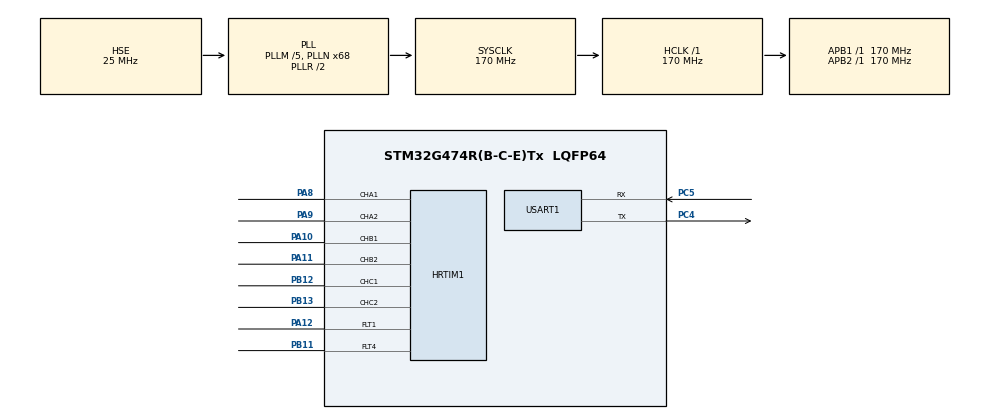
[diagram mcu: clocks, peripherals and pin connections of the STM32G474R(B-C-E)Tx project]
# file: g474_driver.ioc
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HRTIM1.CompareUnit1-Output_TA1TA2=HRTIM_COMPAREUNIT_1
HRTIM1.Periode_TA=34000
HRTIM1.PrescalerRatio_TA=HRTIM_PRESCALERRATIO_MUL4
Mcu.Family=STM32G4
Mcu.Name=STM32G474R(B-C-E)Tx
Mcu.Package=LQFP64
NVIC.PriorityGroup=NVIC_PRIORITYGROUP_4
PA10.Mode=Output_TB1TB2
PA10.Signal=HRTIM1_CHB1
PA11.Mode=Output_TB1TB2
PA11.Signal=HRTIM1_CHB2
PA12.Mode=Fault_Enable1
PA12.Signal=HRTIM1_FLT1
PA13.Mode=Serial_Wire
PA13.Signal=SYS_JTMS-SWDIO
PA14.Mode=Serial_Wire
PA14.Signal=SYS_JTCK-SWCLK
PA8.Mode=Output_TA1TA2
PA8.Signal=HRTIM1_CHA1
PA9.Mode=Output_TA1TA2
PA9.Signal=HRTIM1_CHA2
PB11.Mode=Fault_Enable4
PB11.Signal=HRTIM1_FLT4
PB12.Mode=Output_TC1TC2
PB12.Signal=HRTIM1_CHC1
PB13.Mode=Output_TC1TC2
PB13.Signal=HRTIM1_CHC2
PC4.Mode=Asynchronous
PC4.Signal=USART1_TX
PC5.Mode=Asynchronous
PC5.Signal=USART1_RX
PF0-OSC_IN.Mode=HSE-External-Oscillator
PF0-OSC_IN.Signal=RCC_OSC_IN
PF1-OSC_OUT.Mode=HSE-External-Oscillator
PF1-OSC_OUT.Signal=RCC_OSC_OUT
ProjectManager.HeapSize=0x200
ProjectManager.StackSize=0x400
ProjectManager.TargetToolchain=MDK-ARM V5.32
RCC.ADC12Freq_Value=170000000
RCC.ADC345Freq_Value=170000000
RCC.AHBFreq_Value=170000000
RCC.APB1Freq_Value=170000000
RCC.APB1TimFreq_Value=170000000
RCC.APB2Freq_Value=170000000
RCC.APB2TimFreq_Value=170000000
RCC.CortexFreq_Value=170000000
RCC.EXTERNAL_CLOCK_VALUE=12288000
RCC.HCLKFreq_Value=170000000
RCC.HSE_VALUE=25000000
RCC.HSI48_VALUE=48000000
RCC.HSI_VALUE=16000000
RCC.LSE_VALUE=32768
RCC.PLLM=RCC_PLLM_DIV5
RCC.PLLN=68
RCC.PLLSourceVirtual=RCC_PLLSOURCE_HSE
RCC.SYSCLKFreq_VALUE=170000000
RCC.SYSCLKSource=RCC_SYSCLKSOURCE_PLLCLK
RCC.USART1CLockSelection=RCC_USART1CLKSOURCE_HSI
RCC.USBFreq_Value=170000000
RCC.VCOOutputFreq_Value=340000000
USART1.VirtualMode-Asynchronous=VM_ASYNC
VP_HRTIM1_VS_hrtimMasterTimerNoOutput.Mode=MasterTimer
VP_SYS_VS_DBSignals.Mode=DisableDeadBatterySignals
board=custom

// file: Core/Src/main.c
/* USER CODE BEGIN Header */
/**
  ******************************************************************************
  * @file           : main.c
  * @brief          : Main program body
  ******************************************************************************
  * @attention
  *
  * Copyright (c) 2026 STMicroelectronics.
  * All rights reserved.
  *
  * This software is licensed under terms that can be found in the LICENSE file
  * in the root directory of this software component.
  * If no LICENSE file comes with this software, it is provided AS-IS.
  *
  ******************************************************************************
  */
/* USER CODE END Header */
#include "main.h"

/* USER CODE BEGIN Includes */
//#include "motor.h"
#include "uart.h"
/* USER CODE END Includes */

HRTIM_HandleTypeDef hhrtim1;

UART_HandleTypeDef huart1;

void SystemClock_Config(void);
static void MX_GPIO_Init(void);
static void MX_HRTIM1_Init(void);
static void MX_USART1_UART_Init(void);

int main(void)
{

  /* MCU Configuration--------------------------------------------------------*/

  /* Reset of all peripherals, Initializes the Flash interface and the Systick. */
  HAL_Init();

  /* Configure the system clock */
  SystemClock_Config();

  /* Initialize all configured peripherals */
  MX_GPIO_Init();
  MX_HRTIM1_Init();
  MX_USART1_UART_Init();
  /* USER CODE BEGIN 2 */

  //Motor_Init();
  /* USER CODE END 2 */

  /* Infinite loop */
  while (1)
  {

    /* USER CODE BEGIN 3 */
    //Motor_Update();
	  UART1_SendByte(8);
	  HAL_Delay(500);
  }
  /* USER CODE END 3 */
}

void SystemClock_Config(void)
{
  RCC_OscInitTypeDef RCC_OscInitStruct = {0};
  RCC_ClkInitTypeDef RCC_ClkInitStruct = {0};

  /** Configure the main internal regulator output voltage
  */
  HAL_PWREx_ControlVoltageScaling(PWR_REGULATOR_VOLTAGE_SCALE1_BOOST);

  /** Initializes the RCC Oscillators according to the specified parameters
  * in the RCC_OscInitTypeDef structure.
  */
  RCC_OscInitStruct.OscillatorType = RCC_OSCILLATORTYPE_HSI|RCC_OSCILLATORTYPE_HSE;
  RCC_OscInitStruct.HSEState = RCC_HSE_ON;
  RCC_OscInitStruct.HSIState = RCC_HSI_ON;
  RCC_OscInitStruct.HSICalibrationValue = RCC_HSICALIBRATION_DEFAULT;
  RCC_OscInitStruct.PLL.PLLState = RCC_PLL_ON;
  RCC_OscInitStruct.PLL.PLLSource = RCC_PLLSOURCE_HSE;
  RCC_OscInitStruct.PLL.PLLM = RCC_PLLM_DIV5;
  RCC_OscInitStruct.PLL.PLLN = 68;
  RCC_OscInitStruct.PLL.PLLP = RCC_PLLP_DIV2;
  RCC_OscInitStruct.PLL.PLLQ = RCC_PLLQ_DIV2;
  RCC_OscInitStruct.PLL.PLLR = RCC_PLLR_DIV2;
  if (HAL_RCC_OscConfig(&RCC_OscInitStruct) != HAL_OK)
  {
    Error_Handler();
  }

  /** Initializes the CPU, AHB and APB buses clocks
  */
  RCC_ClkInitStruct.ClockType = RCC_CLOCKTYPE_HCLK|RCC_CLOCKTYPE_SYSCLK
                              |RCC_CLOCKTYPE_PCLK1|RCC_CLOCKTYPE_PCLK2;
  RCC_ClkInitStruct.SYSCLKSource = RCC_SYSCLKSOURCE_PLLCLK;
  RCC_ClkInitStruct.AHBCLKDivider = RCC_SYSCLK_DIV1;
  RCC_ClkInitStruct.APB1CLKDivider = RCC_HCLK_DIV1;
  RCC_ClkInitStruct.APB2CLKDivider = RCC_HCLK_DIV1;

  if (HAL_RCC_ClockConfig(&RCC_ClkInitStruct, FLASH_LATENCY_4) != HAL_OK)
  {
    Error_Handler();
  }
}

static void MX_HRTIM1_Init(void)
{

  HRTIM_FaultCfgTypeDef pFaultCfg = {0};
  HRTIM_FaultBlankingCfgTypeDef pFaultBlkCfg = {0};
  HRTIM_TimeBaseCfgTypeDef pTimeBaseCfg = {0};
  HRTIM_TimerCtlTypeDef pTimerCtl = {0};
  HRTIM_TimerCfgTypeDef pTimerCfg = {0};
  HRTIM_CompareCfgTypeDef pCompareCfg = {0};
  HRTIM_DeadTimeCfgTypeDef pDeadTimeCfg = {0};
  HRTIM_OutputCfgTypeDef pOutputCfg = {0};

  hhrtim1.Instance = HRTIM1;
  hhrtim1.Init.HRTIMInterruptResquests = HRTIM_IT_NONE;
  hhrtim1.Init.SyncOptions = HRTIM_SYNCOPTION_NONE;
  if (HAL_HRTIM_Init(&hhrtim1) != HAL_OK)
  {
    Error_Handler();
  }
  if (HAL_HRTIM_DLLCalibrationStart(&hhrtim1, HRTIM_CALIBRATIONRATE_3) != HAL_OK)
  {
    Error_Handler();
  }
  if (HAL_HRTIM_PollForDLLCalibration(&hhrtim1, 10) != HAL_OK)
  {
    Error_Handler();
  }
  if (HAL_HRTIM_FaultPrescalerConfig(&hhrtim1, HRTIM_FAULTPRESCALER_DIV1) != HAL_OK)
  {
    Error_Handler();
  }
  pFaultCfg.Source = HRTIM_FAULTSOURCE_DIGITALINPUT;
  pFaultCfg.Polarity = HRTIM_FAULTPOLARITY_HIGH;
  pFaultCfg.Filter = HRTIM_FAULTFILTER_NONE;
  pFaultCfg.Lock = HRTIM_FAULTLOCK_READWRITE;
  if (HAL_HRTIM_FaultConfig(&hhrtim1, HRTIM_FAULT_1, &pFaultCfg) != HAL_OK)
  {
    Error_Handler();
  }
  pFaultBlkCfg.Threshold = 0;
  pFaultBlkCfg.ResetMode = HRTIM_FAULTCOUNTERRST_UNCONDITIONAL;
  pFaultBlkCfg.BlankingSource = HRTIM_FAULTBLANKINGMODE_RSTALIGNED;
  if (HAL_HRTIM_FaultCounterConfig(&hhrtim1, HRTIM_FAULT_1, &pFaultBlkCfg) != HAL_OK)
  {
    Error_Handler();
  }
  if (HAL_HRTIM_FaultBlankingConfigAndEnable(&hhrtim1, HRTIM_FAULT_1, &pFaultBlkCfg) != HAL_OK)
  {
    Error_Handler();
  }
  HAL_HRTIM_FaultModeCtl(&hhrtim1, HRTIM_FAULT_1, HRTIM_FAULTMODECTL_ENABLED);
  if (HAL_HRTIM_FaultCounterConfig(&hhrtim1, HRTIM_FAULT_4, &pFaultBlkCfg) != HAL_OK)
  {
    Error_Handler();
  }
  if (HAL_HRTIM_FaultBlankingConfigAndEnable(&hhrtim1, HRTIM_FAULT_4, &pFaultBlkCfg) != HAL_OK)
  {
    Error_Handler();
  }
  if (HAL_HRTIM_FaultConfig(&hhrtim1, HRTIM_FAULT_4, &pFaultCfg) != HAL_OK)
  {
    Error_Handler();
  }
  HAL_HRTIM_FaultModeCtl(&hhrtim1, HRTIM_FAULT_4, HRTIM_FAULTMODECTL_ENABLED);
  pTimeBaseCfg.Period = 34000;
  pTimeBaseCfg.RepetitionCounter = 0x00;
  pTimeBaseCfg.PrescalerRatio = HRTIM_PRESCALERRATIO_MUL4;
  pTimeBaseCfg.Mode = HRTIM_MODE_CONTINUOUS;
  if (HAL_HRTIM_TimeBaseConfig(&hhrtim1, HRTIM_TIMERINDEX_TIMER_A, &pTimeBaseCfg) != HAL_OK)
  {
    Error_Handler();
  }
  pTimerCtl.UpDownMode = HRTIM_TIMERUPDOWNMODE_UP;
  pTimerCtl.GreaterCMP1 = HRTIM_TIMERGTCMP1_EQUAL;
  pTimerCtl.DualChannelDacEnable = HRTIM_TIMER_DCDE_DISABLED;
  if (HAL_HRTIM_WaveformTimerControl(&hhrtim1, HRTIM_TIMERINDEX_TIMER_A, &pTimerCtl) != HAL_OK)
  {
    Error_Handler();
  }
  pTimerCfg.InterruptRequests = HRTIM_TIM_IT_NONE;
  pTimerCfg.DMARequests = HRTIM_TIM_DMA_NONE;
  pTimerCfg.DMASrcAddress = 0x0000;
  pTimerCfg.DMADstAddress = 0x0000;
  pTimerCfg.DMASize = 0x1;
  pTimerCfg.HalfModeEnable = HRTIM_HALFMODE_DISABLED;
  pTimerCfg.InterleavedMode = HRTIM_INTERLEAVED_MODE_DISABLED;
  pTimerCfg.StartOnSync = HRTIM_SYNCSTART_DISABLED;
  pTimerCfg.ResetOnSync = HRTIM_SYNCRESET_DISABLED;
  pTimerCfg.DACSynchro = HRTIM_DACSYNC_NONE;
  pTimerCfg.PreloadEnable = HRTIM_PRELOAD_ENABLED;
  pTimerCfg.UpdateGating = HRTIM_UPDATEGATING_INDEPENDENT;
  pTimerCfg.BurstMode = HRTIM_TIMERBURSTMODE_MAINTAINCLOCK;
  pTimerCfg.RepetitionUpdate = HRTIM_UPDATEONREPETITION_ENABLED;
  pTimerCfg.PushPull = HRTIM_TIMPUSHPULLMODE_DISABLED;
  pTimerCfg.FaultEnable = HRTIM_TIMFAULTENABLE_NONE;
  pTimerCfg.FaultLock = HRTIM_TIMFAULTLOCK_READWRITE;
  pTimerCfg.DeadTimeInsertion = HRTIM_TIMDEADTIMEINSERTION_ENABLED;
  pTimerCfg.DelayedProtectionMode = HRTIM_TIMER_A_B_C_DELAYEDPROTECTION_DISABLED;
  pTimerCfg.UpdateTrigger = HRTIM_TIMUPDATETRIGGER_NONE;
  pTimerCfg.ResetTrigger = HRTIM_TIMRESETTRIGGER_NONE;
  pTimerCfg.ResetUpdate = HRTIM_TIMUPDATEONRESET_DISABLED;
  pTimerCfg.ReSyncUpdate = HRTIM_TIMERESYNC_UPDATE_UNCONDITIONAL;
  if (HAL_HRTIM_WaveformTimerConfig(&hhrtim1, HRTIM_TIMERINDEX_TIMER_A, &pTimerCfg) != HAL_OK)
  {
    Error_Handler();
  }
  if (HAL_HRTIM_WaveformTimerConfig(&hhrtim1, HRTIM_TIMERINDEX_TIMER_B, &pTimerCfg) != HAL_OK)
  {
    Error_Handler();
  }
  if (HAL_HRTIM_WaveformTimerConfig(&hhrtim1, HRTIM_TIMERINDEX_TIMER_C, &pTimerCfg) != HAL_OK)
  {
    Error_Handler();
  }
  pTimerCfg.PreloadEnable = HRTIM_PRELOAD_DISABLED;
  pTimerCfg.RepetitionUpdate = HRTIM_UPDATEONREPETITION_DISABLED;
  pTimerCfg.DeadTimeInsertion = HRTIM_TIMDEADTIMEINSERTION_DISABLED;
  pTimerCfg.DelayedProtectionMode = HRTIM_TIMER_D_E_DELAYEDPROTECTION_DISABLED;
  if (HAL_HRTIM_WaveformTimerConfig(&hhrtim1, HRTIM_TIMERINDEX_TIMER_D, &pTimerCfg) != HAL_OK)
  {
    Error_Handler();
  }
  if (HAL_HRTIM_WaveformTimerConfig(&hhrtim1, HRTIM_TIMERINDEX_TIMER_E, &pTimerCfg) != HAL_OK)
  {
    Error_Handler();
  }
  pTimerCfg.DelayedProtectionMode = HRTIM_TIMER_F_DELAYEDPROTECTION_DISABLED;
  if (HAL_HRTIM_WaveformTimerConfig(&hhrtim1, HRTIM_TIMERINDEX_TIMER_F, &pTimerCfg) != HAL_OK)
  {
    Error_Handler();
  }
  pCompareCfg.CompareValue = 0xFFFB;
  if (HAL_HRTIM_WaveformCompareConfig(&hhrtim1, HRTIM_TIMERINDEX_TIMER_A, HRTIM_COMPAREUNIT_1, &pCompareCfg) != HAL_OK)
  {
    Error_Handler();
  }
  pDeadTimeCfg.Prescaler = HRTIM_TIMDEADTIME_PRESCALERRATIO_MUL8;
  pDeadTimeCfg.RisingValue = 272;
  pDeadTimeCfg.RisingSign = HRTIM_TIMDEADTIME_RISINGSIGN_POSITIVE;
  pDeadTimeCfg.RisingLock = HRTIM_TIMDEADTIME_RISINGLOCK_WRITE;
  pDeadTimeCfg.RisingSignLock = HRTIM_TIMDEADTIME_RISINGSIGNLOCK_WRITE;
  pDeadTimeCfg.FallingValue = 272;
  pDeadTimeCfg.FallingSign = HRTIM_TIMDEADTIME_FALLINGSIGN_POSITIVE;
  pDeadTimeCfg.FallingLock = HRTIM_TIMDEADTIME_FALLINGLOCK_WRITE;
  pDeadTimeCfg.FallingSignLock = HRTIM_TIMDEADTIME_FALLINGSIGNLOCK_WRITE;
  if (HAL_HRTIM_DeadTimeConfig(&hhrtim1, HRTIM_TIMERINDEX_TIMER_A, &pDeadTimeCfg) != HAL_OK)
  {
    Error_Handler();
  }
  if (HAL_HRTIM_DeadTimeConfig(&hhrtim1, HRTIM_TIMERINDEX_TIMER_B, &pDeadTimeCfg) != HAL_OK)
  {
    Error_Handler();
  }
  if (HAL_HRTIM_DeadTimeConfig(&hhrtim1, HRTIM_TIMERINDEX_TIMER_C, &pDeadTimeCfg) != HAL_OK)
  {
    Error_Handler();
  }
  pOutputCfg.Polarity = HRTIM_OUTPUTPOLARITY_HIGH;
  pOutputCfg.SetSource = HRTIM_OUTPUTSET_TIMPER;
  pOutputCfg.ResetSource = HRTIM_OUTPUTRESET_TIMCMP1;
  pOutputCfg.IdleMode = HRTIM_OUTPUTIDLEMODE_NONE;
  pOutputCfg.IdleLevel = HRTIM_OUTPUTIDLELEVEL_INACTIVE;
  pOutputCfg.FaultLevel = HRTIM_OUTPUTFAULTLEVEL_NONE;
  pOutputCfg.ChopperModeEnable = HRTIM_OUTPUTCHOPPERMODE_DISABLED;
  pOutputCfg.BurstModeEntryDelayed = HRTIM_OUTPUTBURSTMODEENTRY_REGULAR;
  if (HAL_HRTIM_WaveformOutputConfig(&hhrtim1, HRTIM_TIMERINDEX_TIMER_A, HRTIM_OUTPUT_TA1, &pOutputCfg) != HAL_OK)
  {
    Error_Handler();
  }
  if (HAL_HRTIM_WaveformOutputConfig(&hhrtim1, HRTIM_TIMERINDEX_TIMER_B, HRTIM_OUTPUT_TB1, &pOutputCfg) != HAL_OK)
  {
    Error_Handler();
  }
  if (HAL_HRTIM_WaveformOutputConfig(&hhrtim1, HRTIM_TIMERINDEX_TIMER_C, HRTIM_OUTPUT_TC1, &pOutputCfg) != HAL_OK)
  {
    Error_Handler();
  }
  pOutputCfg.SetSource = HRTIM_OUTPUTSET_NONE;
  pOutputCfg.ResetSource = HRTIM_OUTPUTRESET_NONE;
  if (HAL_HRTIM_WaveformOutputConfig(&hhrtim1, HRTIM_TIMERINDEX_TIMER_D, HRTIM_OUTPUT_TD1, &pOutputCfg) != HAL_OK)
  {
    Error_Handler();
  }
  if (HAL_HRTIM_WaveformOutputConfig(&hhrtim1, HRTIM_TIMERINDEX_TIMER_E, HRTIM_OUTPUT_TE1, &pOutputCfg) != HAL_OK)
  {
    Error_Handler();
  }
  if (HAL_HRTIM_WaveformOutputConfig(&hhrtim1, HRTIM_TIMERINDEX_TIMER_F, HRTIM_OUTPUT_TF1, &pOutputCfg) != HAL_OK)
  {
    Error_Handler();
  }
  if (HAL_HRTIM_WaveformOutputConfig(&hhrtim1, HRTIM_TIMERINDEX_TIMER_A, HRTIM_OUTPUT_TA2, &pOutputCfg) != HAL_OK)
  {
    Error_Handler();
  }
  if (HAL_HRTIM_WaveformOutputConfig(&hhrtim1, HRTIM_TIMERINDEX_TIMER_B, HRTIM_OUTPUT_TB2, &pOutputCfg) != HAL_OK)
  {
    Error_Handler();
  }
  if (HAL_HRTIM_WaveformOutputConfig(&hhrtim1, HRTIM_TIMERINDEX_TIMER_C, HRTIM_OUTPUT_TC2, &pOutputCfg) != HAL_OK)
  {
    Error_Handler();
  }
  if (HAL_HRTIM_WaveformOutputConfig(&hhrtim1, HRTIM_TIMERINDEX_TIMER_D, HRTIM_OUTPUT_TD2, &pOutputCfg) != HAL_OK)
  {
    Error_Handler();
  }
  if (HAL_HRTIM_WaveformOutputConfig(&hhrtim1, HRTIM_TIMERINDEX_TIMER_E, HRTIM_OUTPUT_TE2, &pOutputCfg) != HAL_OK)
  {
    Error_Handler();
  }
  if (HAL_HRTIM_WaveformOutputConfig(&hhrtim1, HRTIM_TIMERINDEX_TIMER_F, HRTIM_OUTPUT_TF2, &pOutputCfg) != HAL_OK)
  {
    Error_Handler();
  }
  if (HAL_HRTIM_TimeBaseConfig(&hhrtim1, HRTIM_TIMERINDEX_TIMER_B, &pTimeBaseCfg) != HAL_OK)
  {
    Error_Handler();
  }
  if (HAL_HRTIM_WaveformTimerControl(&hhrtim1, HRTIM_TIMERINDEX_TIMER_B, &pTimerCtl) != HAL_OK)
  {
    Error_Handler();
  }
  if (HAL_HRTIM_WaveformCompareConfig(&hhrtim1, HRTIM_TIMERINDEX_TIMER_B, HRTIM_COMPAREUNIT_1, &pCompareCfg) != HAL_OK)
  {
    Error_Handler();
  }
  if (HAL_HRTIM_TimeBaseConfig(&hhrtim1, HRTIM_TIMERINDEX_TIMER_C, &pTimeBaseCfg) != HAL_OK)
  {
    Error_Handler();
  }
  if (HAL_HRTIM_WaveformTimerControl(&hhrtim1, HRTIM_TIMERINDEX_TIMER_C, &pTimerCtl) != HAL_OK)
  {
    Error_Handler();
  }
  if (HAL_HRTIM_WaveformCompareConfig(&hhrtim1, HRTIM_TIMERINDEX_TIMER_C, HRTIM_COMPAREUNIT_1, &pCompareCfg) != HAL_OK)
  {
    Error_Handler();
  }
  pTimeBaseCfg.Period = 0xFFDF;
  pTimeBaseCfg.PrescalerRatio = HRTIM_PRESCALERRATIO_MUL32;
  if (HAL_HRTIM_TimeBaseConfig(&hhrtim1, HRTIM_TIMERINDEX_TIMER_D, &pTimeBaseCfg) != HAL_OK)
  {
    Error_Handler();
  }
  if (HAL_HRTIM_WaveformTimerControl(&hhrtim1, HRTIM_TIMERINDEX_TIMER_D, &pTimerCtl) != HAL_OK)
  {
    Error_Handler();
  }
  if (HAL_HRTIM_TimeBaseConfig(&hhrtim1, HRTIM_TIMERINDEX_TIMER_E, &pTimeBaseCfg) != HAL_OK)
  {
    Error_Handler();
  }
  if (HAL_HRTIM_WaveformTimerControl(&hhrtim1, HRTIM_TIMERINDEX_TIMER_E, &pTimerCtl) != HAL_OK)
  {
    Error_Handler();
  }
  if (HAL_HRTIM_TimeBaseConfig(&hhrtim1, HRTIM_TIMERINDEX_TIMER_F, &pTimeBaseCfg) != HAL_OK)
  {
    Error_Handler();
  }
  if (HAL_HRTIM_WaveformTimerControl(&hhrtim1, HRTIM_TIMERINDEX_TIMER_F, &pTimerCtl) != HAL_OK)
  {
    Error_Handler();
  }
  HAL_HRTIM_MspPostInit(&hhrtim1);

}

static void MX_USART1_UART_Init(void)
{

  huart1.Instance = USART1;
  huart1.Init.BaudRate = 115200;
  huart1.Init.WordLength = UART_WORDLENGTH_8B;
  huart1.Init.StopBits = UART_STOPBITS_1;
  huart1.Init.Parity = UART_PARITY_NONE;
  huart1.Init.Mode = UART_MODE_TX_RX;
  huart1.Init.HwFlowCtl = UART_HWCONTROL_NONE;
  huart1.Init.OverSampling = UART_OVERSAMPLING_16;
  huart1.Init.OneBitSampling = UART_ONE_BIT_SAMPLE_DISABLE;
  huart1.Init.ClockPrescaler = UART_PRESCALER_DIV1;
  huart1.AdvancedInit.AdvFeatureInit = UART_ADVFEATURE_NO_INIT;
  if (HAL_UART_Init(&huart1) != HAL_OK)
  {
    Error_Handler();
  }
  if (HAL_UARTEx_SetTxFifoThreshold(&huart1, UART_TXFIFO_THRESHOLD_1_8) != HAL_OK)
  {
    Error_Handler();
  }
  if (HAL_UARTEx_SetRxFifoThreshold(&huart1, UART_RXFIFO_THRESHOLD_1_8) != HAL_OK)
  {
    Error_Handler();
  }
  if (HAL_UARTEx_DisableFifoMode(&huart1) != HAL_OK)
  {
    Error_Handler();
  }

}

static void MX_GPIO_Init(void)
{

  /* GPIO Ports Clock Enable */
  __HAL_RCC_GPIOF_CLK_ENABLE();
  __HAL_RCC_GPIOC_CLK_ENABLE();
  __HAL_RCC_GPIOB_CLK_ENABLE();
  __HAL_RCC_GPIOA_CLK_ENABLE();

}

void Error_Handler(void)
{
  __disable_irq();
  while (1)
  {
  }
}
